# SYS register map
Vendor: Texas Instruments
Peripheral module from a debugger description file (folder ucd3138064A).
Registers are 32-bit, access not given, no defined reset value unless marked. A register's access mark holds for its fields unless they carry their own. Offsets are as the file gives them; lines under a group give offsets from that group; [hi:lo] are bit positions; {n}, {i} and the like mark numbered series; 'fields as' and 'values as' point back to an identical list; <NAME> marks a mode.

## SYS
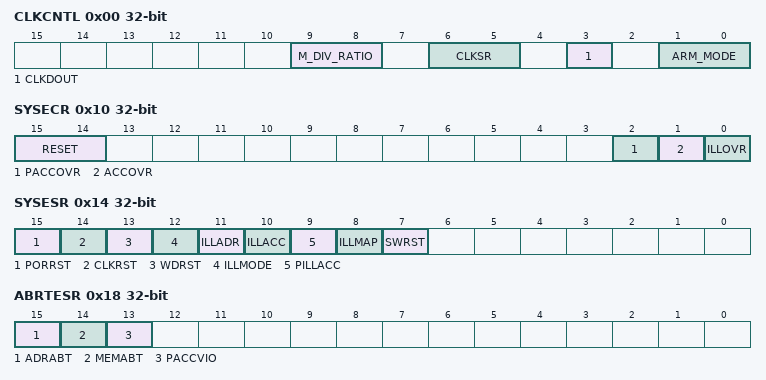
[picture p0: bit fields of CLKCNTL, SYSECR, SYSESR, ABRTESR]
0x00 CLKCNTL — Clock Control Register
  [9:8] M_DIV_RATIO rw — MCLK (processor clock) divide ratio
  [6:5] CLKSR rw — CLKOUT pin source
  [3] CLKDOUT rw — CLKOUT pin output data
  [1:0] ARM_MODE rw
0x10 SYSECR — System Exception Control Register
  [15:14] RESET rw — Software reset
  [2] PACCOVR rw — Peripheral access violation override
  [1] ACCOVR rw — Memory access reset override
  [0] ILLOVR rw — Illegal address reset override
0x10 DEV — Device Identification Register
  [15:0] DEV ro — Device identification code
0x14 SYSESR — System Exception Status Register
  [15] PORRST ro — Power-up reset flag
  [14] CLKRST ro — Clock fail flag
  [13] WDRST ro — Watchdog reset flag
  [12] ILLMODE ro — Illegal mode flag
  [11] ILLADR ro — Illegal address access flag
  [10] ILLACC ro — Illegal memory access flag
  [9] PILLACC ro — Peripheral illegal access flag
  [8] ILLMAP ro — Illegal address map flag
  [7] SWRST ro — Software reset flag
0x18 ABRTESR — Abort Exception Status Register
  [15] ADRABT ro — Illegal address abort
  [14] MEMABT ro — Memory access abort
  [13] PACCVIO ro — Peripheral access violation error
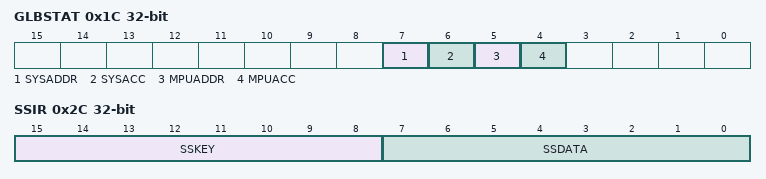
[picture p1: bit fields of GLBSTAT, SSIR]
0x1C GLBSTAT — Global Status Register
  [7] SYSADDR ro — System illegal address flag
  [6] SYSACC ro — System illegal access flag
  [5] MPUADDR ro — MPU illegal address flag
  [4] MPUACC ro — MPU illegal access flag
0x28 SSIF — System Software Interrupt Flag Register
  [0] SSIFLAG ro — System software interrupt flag
0x2C SSIR — System Software Interrupt Request Register
  [15:8] SSKEY rw — System software interrupt request key
  [7:0] SSDATA rw — System software interrupt data
